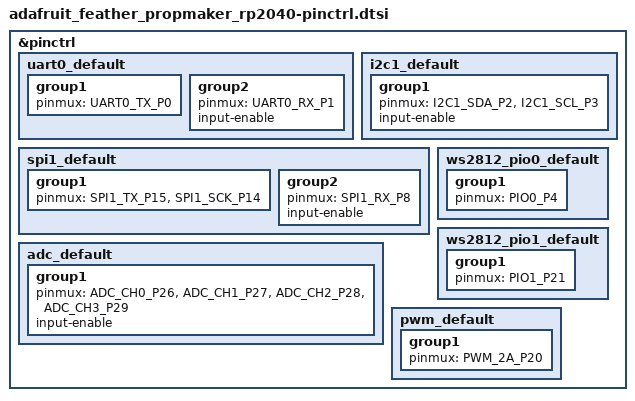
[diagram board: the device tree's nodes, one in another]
/*
 * Copyright (c) 2026 Jonas Berg
 *
 * SPDX-License-Identifier: Apache-2.0
 */

#include <zephyr/dt-bindings/pinctrl/rpi-pico-rp2040-pinctrl.h>

&pinctrl {
	uart0_default: uart0_default {
		group1 {
			pinmux = <UART0_TX_P0>;
		};

		group2 {
			pinmux = <UART0_RX_P1>;
			input-enable;
		};
	};

	i2c1_default: i2c1_default {
		group1 {
			pinmux = <I2C1_SDA_P2>, <I2C1_SCL_P3>;
			input-enable;
		};
	};

	spi1_default: spi1_default {
		group1 {
			pinmux = <SPI1_TX_P15>, <SPI1_SCK_P14>;
		};

		group2 {
			pinmux = <SPI1_RX_P8>;
			input-enable;
		};
	};

	adc_default: adc_default {
		group1 {
			pinmux = <ADC_CH0_P26>, <ADC_CH1_P27>, <ADC_CH2_P28>, <ADC_CH3_P29>;
			input-enable;
		};
	};

	ws2812_pio0_default: ws2812_pio0_default {
		group1 {
			pinmux = <PIO0_P4>;
		};
	};

	ws2812_pio1_default: ws2812_pio1_default {
		group1 {
			pinmux = <PIO1_P21>;
		};
	};

	pwm_default: pwm_default {
		group1 {
			pinmux = <PWM_2A_P20>;
		};
	};
};
